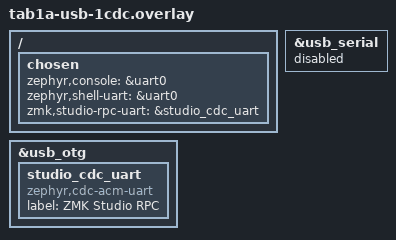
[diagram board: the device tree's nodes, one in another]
/*
 * Copyright (c) 2026 The ZMK Contributors
 *
 * SPDX-License-Identifier: MIT
 *
 * Tab1a USB build: HID + one Studio-RPC CDC; console/shell pinned to UART0.
 *   sh zmk/esp-port/build_cobantab1a.sh -O zmk/esp-port/bringup/tab1a-usb-1cdc.overlay
 * Applied AFTER the shield overlay, so every chosen here wins.
 * Unfused board: GPIO19/20 boot into USB-Serial/JTAG (flash.sh works); the
 * DWC2 driver hands them to OTG when the device stack starts, any reset reverts.
 */

/ {
    chosen {
        /* Console on UART0 (P1 wire): boot logs land there before enumeration.
         * It must not share the RPC's CDC: a UART device carries exactly one
         * IRQ callback, so a shell would silently evict the RPC transport's RX. */
        zephyr,console = &uart0;
        zephyr,shell-uart = &uart0;

        zmk,studio-rpc-uart = &studio_cdc_uart;
    };
};

/* The zephyr_udc0 label is mandatory (app/src/usb.c #error); binding it
 * enables the SoC's DWC2 device controller. */
zephyr_udc0: &usb_otg {
    status = "okay";

    /* No more than two CDCs fit on this composite: 6 IN EPs =
     * EP0 + HID + 2x(CDC data + CDC notify). */
    studio_cdc_uart: studio_cdc_uart {
        compatible = "zephyr,cdc-acm-uart";
        label = "ZMK Studio RPC";
    };

};

/* GPIO19/20 are OTG's at runtime — leave no dead console device on Serial/JTAG. */
&usb_serial {
    status = "disabled";
};
